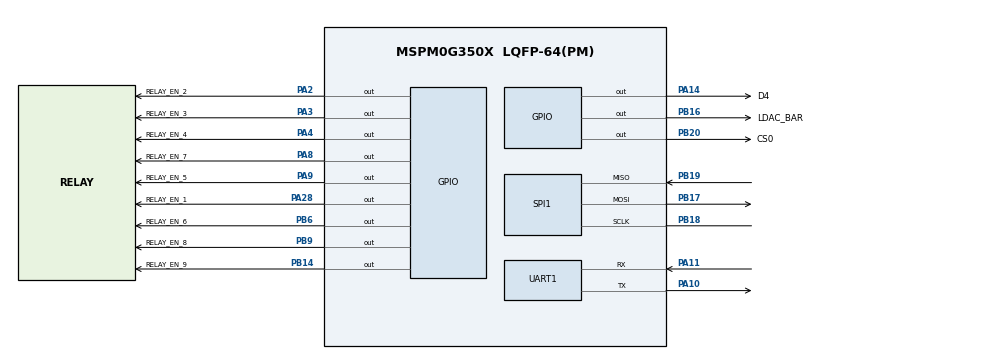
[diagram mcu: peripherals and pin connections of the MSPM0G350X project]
/**
 * @cliArgs --device "MSPM0G350X" --package "LQFP-64(PM)" --part "Default" --product "mspm0_sdk@2.00.00.03"
 * @versions {"tool":"1.19.0+3426"}
 */

/**
 * Import the modules used in this configuration.
 */
const GPIO   = scripting.addModule("/ti/driverlib/GPIO", {}, false);
const GPIO1  = GPIO.addInstance();
const GPIO2  = GPIO.addInstance();
const GPIO3  = GPIO.addInstance();
const SPI    = scripting.addModule("/ti/driverlib/SPI", {}, false);
const SPI1   = SPI.addInstance();
const SYSCTL = scripting.addModule("/ti/driverlib/SYSCTL");
const TIMER  = scripting.addModule("/ti/driverlib/TIMER", {}, false);
const TIMER1 = TIMER.addInstance();
const TIMER2 = TIMER.addInstance();
const UART   = scripting.addModule("/ti/driverlib/UART", {}, false);
const UART1  = UART.addInstance();

/**
 * Write custom configuration values to the imported modules.
 */
GPIO1.$name                         = "Relay";
GPIO1.associatedPins.create(9);
GPIO1.associatedPins[0].$name       = "RELAY_EN_1";
GPIO1.associatedPins[0].pin.$assign = "PA28";
GPIO1.associatedPins[1].$name       = "RELAY_EN_2";
GPIO1.associatedPins[1].pin.$assign = "PA2";
GPIO1.associatedPins[2].$name       = "RELAY_EN_3";
GPIO1.associatedPins[2].pin.$assign = "PA3";
GPIO1.associatedPins[3].$name       = "RELAY_EN_4";
GPIO1.associatedPins[3].pin.$assign = "PA4";
GPIO1.associatedPins[4].$name       = "RELAY_EN_5";
GPIO1.associatedPins[4].pin.$assign = "PA9";
GPIO1.associatedPins[5].$name       = "RELAY_EN_6";
GPIO1.associatedPins[5].pin.$assign = "PB6";
GPIO1.associatedPins[6].$name       = "RELAY_EN_7";
GPIO1.associatedPins[6].pin.$assign = "PA8";
GPIO1.associatedPins[7].$name       = "RELAY_EN_8";
GPIO1.associatedPins[7].pin.$assign = "PB9";
GPIO1.associatedPins[8].$name       = "RELAY_EN_9";
GPIO1.associatedPins[8].pin.$assign = "PB14";

const Board = scripting.addModule("/ti/driverlib/Board", {}, false);

GPIO2.$name                          = "MCU_SPI";
GPIO2.associatedPins.create(2);
GPIO2.associatedPins[0].$name        = "CS0";
GPIO2.associatedPins[0].initialValue = "SET";
GPIO2.associatedPins[0].pin.$assign  = "PB20";
GPIO2.associatedPins[1].$name        = "LDAC_BAR";
GPIO2.associatedPins[1].pin.$assign  = "PB16";

GPIO3.$name                         = "Led";
GPIO3.associatedPins[0].$name       = "D4";
GPIO3.associatedPins[0].pin.$assign = "PA14";

SPI1.$name                      = "SPI_0";
SPI1.frameFormat                = "MOTO3";
SPI1.dataSize                   = 16;
SPI1.targetBitRate              = 16000000;
SPI1.overrideRetention          = true;
SPI1.enabledInterrupts          = ["IDLE","RX","RX_TIMEOUT","TX"];
SPI1.rxFifoThreshold            = "DL_SPI_RX_FIFO_LEVEL_1_4_FULL";
SPI1.txFifoThreshold            = "DL_SPI_TX_FIFO_LEVEL_ONE_FRAME";
SPI1.peripheral.$assign         = "SPI0";
SPI1.peripheral.sclkPin.$assign = "PB18";
SPI1.peripheral.mosiPin.$assign = "PB17";
SPI1.peripheral.misoPin.$assign = "PB19";
SPI1.sclkPinConfig.$name        = "ti_driverlib_gpio_GPIOPinGeneric2";
SPI1.mosiPinConfig.$name        = "ti_driverlib_gpio_GPIOPinGeneric3";
SPI1.misoPinConfig.$name        = "ti_driverlib_gpio_GPIOPinGeneric4";

SYSCTL.forceDefaultClkConfig = true;

TIMER1.$name              = "TIMER_2";
TIMER1.timerClkPrescale   = 32;
TIMER1.interrupts         = ["ZERO"];
TIMER1.timerPeriod        = "65.535 ms";
TIMER1.overrideRetention  = true;
TIMER1.peripheral.$assign = "TIMG7";

TIMER2.$name              = "TIMER_0";
TIMER2.timerMode          = "ONE_SHOT_UP";
TIMER2.interrupts         = ["LOAD"];
TIMER2.overrideRetention  = true;
TIMER2.peripheral.$assign = "TIMA0";

UART1.$name                    = "UART_0";
UART1.targetBaudRate           = 115200;
UART1.enabledInterrupts        = ["BREAK_ERROR","CTS_DONE","DMA_DONE_RX","DMA_DONE_TX","EOT_DONE","FRAMING_ERROR","NOISE_ERROR","OVERRUN_ERROR","PARITY_ERROR","RX","RXD_NEG_EDGE","RXD_POS_EDGE","RX_TIMEOUT_ERROR","TX"];
UART1.enableFIFO               = true;
UART1.txFifoThreshold          = "DL_UART_TX_FIFO_LEVEL_ONE_ENTRY";
UART1.rxFifoThreshold          = "DL_UART_RX_FIFO_LEVEL_1_4_FULL";
UART1.peripheral.$assign       = "UART0";
UART1.peripheral.rxPin.$assign = "PA11";
UART1.peripheral.txPin.$assign = "PA10";
UART1.txPinConfig.$name        = "ti_driverlib_gpio_GPIOPinGeneric0";
UART1.rxPinConfig.$name        = "ti_driverlib_gpio_GPIOPinGeneric1";

/**
 * Pinmux solution for unlocked pins/peripherals. This ensures that minor changes to the automatic solver in a future
 * version of the tool will not impact the pinmux you originally saw.  These lines can be completely deleted in order to
 * re-solve from scratch.
 */
Board.peripheral.$suggestSolution          = "DEBUGSS";
Board.peripheral.swclkPin.$suggestSolution = "PA20";
Board.peripheral.swdioPin.$suggestSolution = "PA19";
SYSCTL.peripheral.$suggestSolution         = "SYSCTL";
